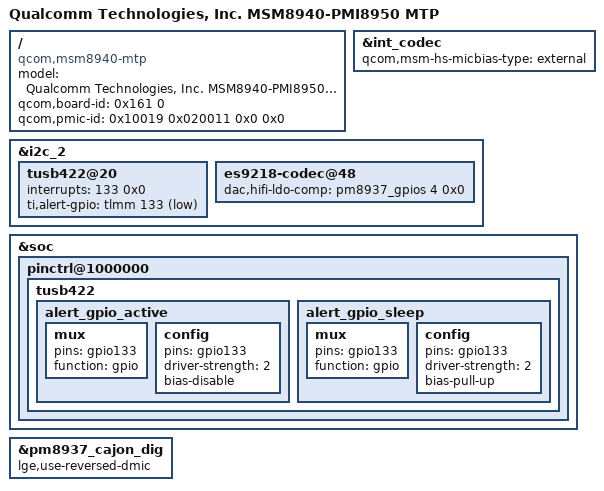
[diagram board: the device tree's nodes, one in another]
/*
 * Copyright (c) 2015-2016, The Linux Foundation. All rights reserved.
 *
 * This program is free software; you can redistribute it and/or modify
 * it under the terms of the GNU General Public License version 2 and
 * only version 2 as published by the Free Software Foundation.

 *
 * This program is distributed in the hope that it will be useful,
 * but WITHOUT ANY WARRANTY; without even the implied warranty of
 * MERCHANTABILITY or FITNESS FOR A PARTICULAR PURPOSE.  See the
 * GNU General Public License for more details.
 */

/dts-v1/;

#include "../../qcom/msm8940.dtsi"
#include "../../qcom/msm-pmi8950.dtsi"
#include "../msm8940-lge-common/msm8940-lge-pmi8950.dtsi"
#include "msm8940-l6_dcm_jp.dtsi"

/ {
	model = "Qualcomm Technologies, Inc. MSM8940-PMI8950 MTP";
	compatible = "qcom,msm8940-mtp", "qcom,msm8940", "qcom,mtp";
	qcom,board-id= <0x161 0>;
	qcom,pmic-id = <0x10019 0x020011 0x0 0x0>;
};

&int_codec {
	qcom,msm-hs-micbias-type = "external";
};

&i2c_2 {
	tusb422@20 {
		interrupts = <133 0x0>;
		ti,alert-gpio = <&tlmm 133 0x1>;
	};

	es9218-codec@48 {
		dac,hifi-ldo-comp = <&pm8937_gpios 4 0x0>;
	};
};

&soc{
	pinctrl@1000000{
		tusb422{
			alert_gpio_active: alert_gpio_active {
				mux {
					pins = "gpio133";
					function = "gpio";
				};
				config {
					pins = "gpio133";
					driver-strength = <2>;
					bias-disable;
				};
			};

			alert_gpio_sleep: alert_gpio_sleep {
				mux {
					pins = "gpio133";
					function = "gpio";
				};

				config {
					pins = "gpio133";
					driver-strength = <2>;
					bias-pull-up;
				};
			};
		};
	};
};

&pm8937_cajon_dig {
	lge,use-reversed-dmic;
};
